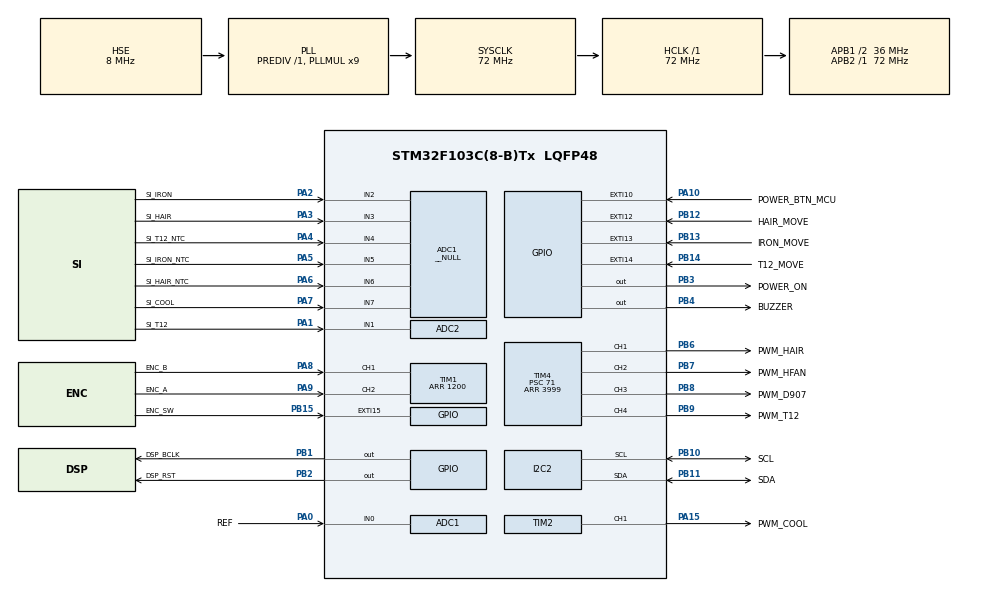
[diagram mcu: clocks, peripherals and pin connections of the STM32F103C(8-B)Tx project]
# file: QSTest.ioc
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ADC1.Channel-0\#ChannelRegularConversion=ADC_CHANNEL_0
ADC1.Channel-1\#ChannelRegularConversion=ADC_CHANNEL_2
ADC1.Channel-10\#ChannelRegularConversion=ADC_CHANNEL_7
ADC1.Channel-6\#ChannelRegularConversion=ADC_CHANNEL_3
ADC1.Channel-7\#ChannelRegularConversion=ADC_CHANNEL_4
ADC1.Channel-8\#ChannelRegularConversion=ADC_CHANNEL_5
ADC1.Channel-9\#ChannelRegularConversion=ADC_CHANNEL_6
ADC1.ContinuousConvMode=ENABLE
ADC1.EnableRegularConversion=ENABLE
ADC1.Mode=__NULL
ADC1.NbrOfConversion=7
ADC1.NbrOfConversionFlag=1
ADC1.Rank-0\#ChannelRegularConversion=1
ADC1.Rank-1\#ChannelRegularConversion=2
ADC1.Rank-10\#ChannelRegularConversion=7
ADC1.Rank-6\#ChannelRegularConversion=3
ADC1.Rank-7\#ChannelRegularConversion=4
ADC1.Rank-8\#ChannelRegularConversion=5
ADC1.Rank-9\#ChannelRegularConversion=6
ADC1.SamplingTime-0\#ChannelRegularConversion=ADC_SAMPLETIME_71CYCLES_5
ADC1.SamplingTime-1\#ChannelRegularConversion=ADC_SAMPLETIME_71CYCLES_5
ADC1.SamplingTime-10\#ChannelRegularConversion=ADC_SAMPLETIME_71CYCLES_5
ADC1.SamplingTime-6\#ChannelRegularConversion=ADC_SAMPLETIME_71CYCLES_5
ADC1.SamplingTime-7\#ChannelRegularConversion=ADC_SAMPLETIME_71CYCLES_5
ADC1.SamplingTime-8\#ChannelRegularConversion=ADC_SAMPLETIME_71CYCLES_5
ADC1.SamplingTime-9\#ChannelRegularConversion=ADC_SAMPLETIME_71CYCLES_5
ADC1.master=1
ADC2.Channel-0\#ChannelRegularConversion=ADC_CHANNEL_1
ADC2.NbrOfConversionFlag=1
ADC2.Rank-0\#ChannelRegularConversion=1
ADC2.SamplingTime-0\#ChannelRegularConversion=ADC_SAMPLETIME_71CYCLES_5
Dma.ADC1.0.Direction=DMA_PERIPH_TO_MEMORY
Dma.ADC1.0.Instance=DMA1_Channel1
Dma.ADC1.0.MemDataAlignment=DMA_MDATAALIGN_HALFWORD
Dma.ADC1.0.MemInc=DMA_MINC_ENABLE
Dma.ADC1.0.Mode=DMA_CIRCULAR
Dma.ADC1.0.PeriphDataAlignment=DMA_PDATAALIGN_HALFWORD
Dma.ADC1.0.PeriphInc=DMA_PINC_DISABLE
Dma.ADC1.0.Priority=DMA_PRIORITY_LOW
Dma.Request0=ADC1
I2C2.AddressingMode=I2C_ADDRESSINGMODE_7BIT
I2C2.DualAddressMode=I2C_DUALADDRESS_DISABLE
I2C2.GeneralCallMode=I2C_GENERALCALL_DISABLE
I2C2.I2C_Mode=I2C_Fast
I2C2.NoStretchMode=I2C_NOSTRETCH_DISABLE
Mcu.Family=STM32F1
Mcu.Name=STM32F103C(8-B)Tx
Mcu.Package=LQFP48
NVIC.DMA1_Channel1_IRQn=true\:0\:0\:false\:false\:true\:false\:true\:true
NVIC.EXTI15_10_IRQn=true\:0\:0\:false\:false\:true\:true\:true\:true
NVIC.PriorityGroup=NVIC_PRIORITYGROUP_4
PA0-WKUP.GPIO_Label=REF
PA0-WKUP.Signal=ADCx_IN0
PA1.GPIO_Label=SI_T12
PA1.Signal=ADCx_IN1
PA10.GPIO_Label=POWER_BTN_MCU
PA10.GPIO_ModeDefaultEXTI=GPIO_MODE_IT_FALLING
PA10.Signal=GPXTI10
PA13.Mode=Serial_Wire
PA13.Signal=SYS_JTMS-SWDIO
PA14.Mode=Serial_Wire
PA14.Signal=SYS_JTCK-SWCLK
PA15.GPIO_Label=PWM_COOL
PA15.Signal=S_TIM2_CH1_ETR
PA2.GPIO_Label=SI_IRON
PA2.Signal=ADCx_IN2
PA3.GPIO_Label=SI_HAIR
PA3.Signal=ADCx_IN3
PA4.GPIO_Label=SI_T12_NTC
PA4.Signal=ADCx_IN4
PA5.GPIO_Label=SI_IRON_NTC
PA5.Signal=ADCx_IN5
PA6.GPIO_Label=SI_HAIR_NTC
PA6.Signal=ADCx_IN6
PA7.GPIO_Label=SI_COOL
PA7.Signal=ADCx_IN7
PA8.GPIO_Label=ENC_B
PA8.Signal=S_TIM1_CH1
PA9.GPIO_Label=ENC_A
PA9.Signal=S_TIM1_CH2
PB1.GPIO_Label=DSP_BCLK
PB1.Signal=GPIO_Output
PB10.GPIO_Label=SCL
PB10.Mode=I2C
PB10.Signal=I2C2_SCL
PB11.GPIO_Label=SDA
PB11.Mode=I2C
PB11.Signal=I2C2_SDA
PB12.GPIO_Label=HAIR_MOVE
PB12.GPIO_ModeDefaultEXTI=GPIO_MODE_IT_FALLING
PB12.Signal=GPXTI12
PB13.GPIO_Label=IRON_MOVE
PB13.GPIO_ModeDefaultEXTI=GPIO_MODE_IT_FALLING
PB13.Signal=GPXTI13
PB14.GPIO_Label=T12_MOVE
PB14.GPIO_ModeDefaultEXTI=GPIO_MODE_IT_RISING
PB14.GPIO_PuPd=GPIO_NOPULL
PB14.Signal=GPXTI14
PB15.GPIO_Label=ENC_SW
PB15.GPIO_ModeDefaultEXTI=GPIO_MODE_IT_FALLING
PB15.Signal=GPXTI15
PB2.GPIO_Label=DSP_RST
PB2.Signal=GPIO_Output
PB3.GPIO_Label=POWER_ON
PB3.Signal=GPIO_Output
PB4.GPIO_Label=BUZZER
PB4.GPIO_PuPd=GPIO_PULLDOWN
PB4.GPIO_Speed=GPIO_SPEED_FREQ_MEDIUM
PB4.PinState=GPIO_PIN_RESET
PB4.Signal=GPIO_Output
PB6.GPIO_Label=PWM_HAIR
PB6.GPIO_ModeDefaultPP=GPIO_MODE_AF_PP
PB6.Signal=S_TIM4_CH1
PB7.GPIO_Label=PWM_HFAN
PB7.Signal=S_TIM4_CH2
PB8.GPIO_Label=PWM_D907
PB8.Signal=S_TIM4_CH3
PB9.GPIO_Label=PWM_T12
PB9.Signal=S_TIM4_CH4
PD0-OSC_IN.Mode=HSE-External-Oscillator
PD0-OSC_IN.Signal=RCC_OSC_IN
PD1-OSC_OUT.Mode=HSE-External-Oscillator
PD1-OSC_OUT.Signal=RCC_OSC_OUT
ProjectManager.HeapSize=0x8192
ProjectManager.StackSize=0x12288
ProjectManager.TargetToolchain=Makefile
RCC.ADCPresc=RCC_ADCPCLK2_DIV6
RCC.AHBFreq_Value=72000000
RCC.APB1CLKDivider=RCC_HCLK_DIV2
RCC.APB1Freq_Value=36000000
RCC.APB1TimFreq_Value=72000000
RCC.APB2Freq_Value=72000000
RCC.APB2TimFreq_Value=72000000
RCC.HCLKFreq_Value=72000000
RCC.PLLMUL=RCC_PLL_MUL9
RCC.PLLSourceVirtual=RCC_PLLSOURCE_HSE
RCC.SYSCLKFreq_VALUE=72000000
RCC.SYSCLKSource=RCC_SYSCLKSOURCE_PLLCLK
RCC.USBFreq_Value=72000000
SH.ADCx_IN0.0=ADC1_IN0,IN0
SH.ADCx_IN1.0=ADC2_IN1,IN1
SH.ADCx_IN2.0=ADC1_IN2,IN2
SH.ADCx_IN3.0=ADC1_IN3,IN3
SH.ADCx_IN4.0=ADC1_IN4,IN4
SH.ADCx_IN5.0=ADC1_IN5,IN5
SH.ADCx_IN6.0=ADC1_IN6,IN6
SH.ADCx_IN7.0=ADC1_IN7,IN7
SH.S_TIM1_CH1.0=TIM1_CH1,Encoder_Interface
SH.S_TIM1_CH2.0=TIM1_CH2,Encoder_Interface
SH.S_TIM2_CH1_ETR.0=TIM2_CH1,PWM Generation1 CH1
SH.S_TIM4_CH1.0=TIM4_CH1,PWM Generation1 CH1
SH.S_TIM4_CH2.0=TIM4_CH2,PWM Generation2 CH2
SH.S_TIM4_CH3.0=TIM4_CH3,PWM Generation3 CH3
SH.S_TIM4_CH4.0=TIM4_CH4,PWM Generation4 CH4
TIM1.ClockDivision=TIM_CLOCKDIVISION_DIV1
TIM1.CounterMode=TIM_COUNTERMODE_UP
TIM1.EncoderMode=TIM_ENCODERMODE_TI12
TIM1.IC1Filter=15
TIM1.IC1Polarity=TIM_ICPOLARITY_FALLING
TIM1.IC2Filter=15
TIM1.IC2Polarity=TIM_ICPOLARITY_FALLING
TIM1.Period=1200
TIM2.Channel-PWM\ Generation1\ CH1=TIM_CHANNEL_1
TIM2.Period=3999
TIM2.Prescaler=72
TIM4.Channel-PWM\ Generation1\ CH1=TIM_CHANNEL_1
TIM4.Channel-PWM\ Generation2\ CH2=TIM_CHANNEL_2
TIM4.Channel-PWM\ Generation3\ CH3=TIM_CHANNEL_3
TIM4.Channel-PWM\ Generation4\ CH4=TIM_CHANNEL_4
TIM4.OC1Preload_PWM=ENABLE
TIM4.OC2Preload_PWM=ENABLE
TIM4.OC3Preload_PWM=ENABLE
TIM4.OC4Preload_PWM=ENABLE
TIM4.OCFastMode_PWM-PWM\ Generation1\ CH1=TIM_OCFAST_DISABLE
TIM4.OCMode_PWM-PWM\ Generation1\ CH1=TIM_OCMODE_PWM1
TIM4.OCPolarity_1=TIM_OCPOLARITY_HIGH
TIM4.OCPolarity_2=TIM_OCPOLARITY_HIGH
TIM4.OCPolarity_3=TIM_OCPOLARITY_HIGH
TIM4.OCPolarity_4=TIM_OCPOLARITY_HIGH
TIM4.Period=3999
TIM4.Prescaler=71
TIM4.Pulse-PWM\ Generation1\ CH1=3999
TIM4.Pulse-PWM\ Generation2\ CH2=3999
TIM4.Pulse-PWM\ Generation3\ CH3=0
TIM4.Pulse-PWM\ Generation4\ CH4=0
board=custom

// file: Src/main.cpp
/* USER CODE BEGIN Header */
/* USER CODE END Header */
#include "main.h"
#include "adc.h"
#include "dma.h"
#include "i2c.h"
#include "tim.h"
#include "gpio.h"

/* USER CODE BEGIN Includes */
#include "app.hpp"
/* USER CODE END Includes */

void SystemClock_Config(void);

int main(void)
{

  /* MCU Configuration--------------------------------------------------------*/

  /* Reset of all peripherals, Initializes the Flash interface and the Systick. */
  HAL_Init();

  /* Configure the system clock */
  SystemClock_Config();

  /* Initialize all configured peripherals */
  MX_GPIO_Init();
  MX_DMA_Init();
  MX_ADC1_Init();
  MX_I2C2_Init();
  MX_TIM1_Init();
  MX_TIM4_Init();
  MX_TIM2_Init();
  MX_ADC2_Init();
  /* USER CODE BEGIN 2 */
  HAL_TIM_Encoder_Start(&htim1, TIM_CHANNEL_1);
  HAL_TIM_PWM_Start(&htim4, TIM_CHANNEL_1);

  Initialize();
  /* USER CODE END 2 */

  /* Infinite loop */
  while (1)
  {

    /* USER CODE BEGIN 3 */
    Main();
  }
  /* USER CODE END 3 */
}

void SystemClock_Config(void)
{
  RCC_OscInitTypeDef RCC_OscInitStruct = {0};
  RCC_ClkInitTypeDef RCC_ClkInitStruct = {0};
  RCC_PeriphCLKInitTypeDef PeriphClkInit = {0};

  /** Initializes the RCC Oscillators according to the specified parameters
  * in the RCC_OscInitTypeDef structure.
  */
  RCC_OscInitStruct.OscillatorType = RCC_OSCILLATORTYPE_HSE;
  RCC_OscInitStruct.HSEState = RCC_HSE_ON;
  RCC_OscInitStruct.HSEPredivValue = RCC_HSE_PREDIV_DIV1;
  RCC_OscInitStruct.HSIState = RCC_HSI_ON;
  RCC_OscInitStruct.PLL.PLLState = RCC_PLL_ON;
  RCC_OscInitStruct.PLL.PLLSource = RCC_PLLSOURCE_HSE;
  RCC_OscInitStruct.PLL.PLLMUL = RCC_PLL_MUL9;
  if (HAL_RCC_OscConfig(&RCC_OscInitStruct) != HAL_OK)
  {
    Error_Handler();
  }

  /** Initializes the CPU, AHB and APB buses clocks
  */
  RCC_ClkInitStruct.ClockType = RCC_CLOCKTYPE_HCLK|RCC_CLOCKTYPE_SYSCLK
                              |RCC_CLOCKTYPE_PCLK1|RCC_CLOCKTYPE_PCLK2;
  RCC_ClkInitStruct.SYSCLKSource = RCC_SYSCLKSOURCE_PLLCLK;
  RCC_ClkInitStruct.AHBCLKDivider = RCC_SYSCLK_DIV1;
  RCC_ClkInitStruct.APB1CLKDivider = RCC_HCLK_DIV2;
  RCC_ClkInitStruct.APB2CLKDivider = RCC_HCLK_DIV1;

  if (HAL_RCC_ClockConfig(&RCC_ClkInitStruct, FLASH_LATENCY_2) != HAL_OK)
  {
    Error_Handler();
  }
  PeriphClkInit.PeriphClockSelection = RCC_PERIPHCLK_ADC;
  PeriphClkInit.AdcClockSelection = RCC_ADCPCLK2_DIV6;
  if (HAL_RCCEx_PeriphCLKConfig(&PeriphClkInit) != HAL_OK)
  {
    Error_Handler();
  }
}

/* USER CODE BEGIN 4 */
void SysTick_interrupt()
{
  SysTickInterrupt();
}
void HAL_GPIO_EXTI_Callback(uint16_t GPIO_Pin)
{
  PinCallback(GPIO_Pin);
}
void HAL_ADC_ConvCpltCallback(ADC_HandleTypeDef *hadc)
{
  AdcCallback(hadc);
}

/* USER CODE END 4 */

void Error_Handler(void)
{
}
